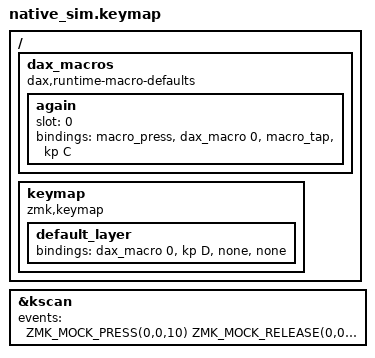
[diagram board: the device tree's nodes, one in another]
#include <behaviors.dtsi>
#include <behaviors/dax_macro.dtsi>
#include <dt-bindings/zmk/keys.h>
#include <dt-bindings/zmk/kscan_mock.h>

// A macro that plays itself, with no wait before it does: each play taps C and starts the next,
// one deeper, until the nesting limit drops one. C comes out five times, nothing stays pressed,
// and the second key still plays afterwards.
/ {
    dax_macros {
        compatible = "dax,runtime-macro-defaults";

        again {
            slot = <0>;
            bindings = <&macro_press &dax_macro 0>, <&macro_tap &kp C>;
        };
    };

    keymap {
        compatible = "zmk,keymap";
        default_layer {
            bindings = <&dax_macro 0 &kp D &none &none>;
        };
    };
};

&kscan {
    events = <
        ZMK_MOCK_PRESS(0,0,10)
        ZMK_MOCK_RELEASE(0,0,1000)
        ZMK_MOCK_PRESS(0,1,10)
        ZMK_MOCK_RELEASE(0,1,100)
    >;
};
